# STM32C031K6U6 register map
File version: 1.0
Registers are 32-bit, access not given, reset 0x0 unless marked. A register's access mark holds for its fields unless they carry their own. Offsets are from the block's base; [hi:lo] are bit positions; {n}, {i} and the like mark numbered series; 'fields as' and 'values as' point back to an identical list.

## SYSCFG
Base 0x40010000
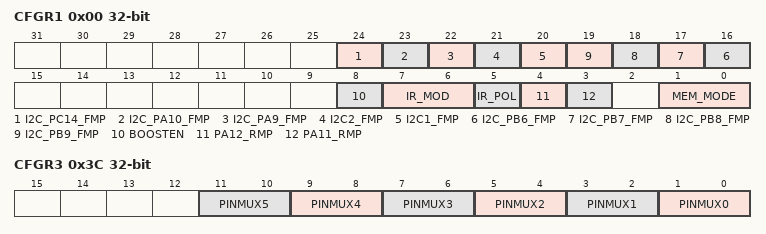
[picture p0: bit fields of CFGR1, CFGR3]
0x00 CFGR1
  [24] I2C_PC14_FMP, [23] I2C_PA10_FMP, [22] I2C_PA9_FMP, [21] I2C2_FMP, [20] I2C1_FMP, [n+10] I2C_PB{n}_FMP (n=6..9), [8] BOOSTEN, [7:6] IR_MOD, [5] IR_POL, [4] PA12_RMP, [3] PA11_RMP, [1:0] MEM_MODE
0x18 CFGR2
  [0] CLL
0x3C CFGR3
  [2n+1:2n] PINMUX{n} (n=0..5)
0x80 IT_LINE_SR.0
0x84 IT_LINE_SR.1
0x88 IT_LINE_SR.2
0x8C IT_LINE_SR.3
0x90 IT_LINE_SR.4
0x94 IT_LINE_SR.5
0x98 IT_LINE_SR.6
0x9C IT_LINE_SR.7
0xA0 IT_LINE_SR.8
0xA4 IT_LINE_SR.9
0xA8 IT_LINE_SR.10
0xAC IT_LINE_SR.11
0xB0 IT_LINE_SR.12
0xB4 IT_LINE_SR.13
0xB8 IT_LINE_SR.14
0xBC IT_LINE_SR.15
0xC0 IT_LINE_SR.16
0xC4 IT_LINE_SR.17
0xC8 IT_LINE_SR.18
0xCC IT_LINE_SR.19
0xD0 IT_LINE_SR.20
0xD4 IT_LINE_SR.21
0xD8 IT_LINE_SR.22
0xDC IT_LINE_SR.23
0xE0 IT_LINE_SR.24
0xE4 IT_LINE_SR.25
0xE8 IT_LINE_SR.26
0xEC IT_LINE_SR.27
0xF0 IT_LINE_SR.28
0xF4 IT_LINE_SR.29
0xF8 IT_LINE_SR.30
0xFC IT_LINE_SR.31

## ADC1
Base 0x40012400
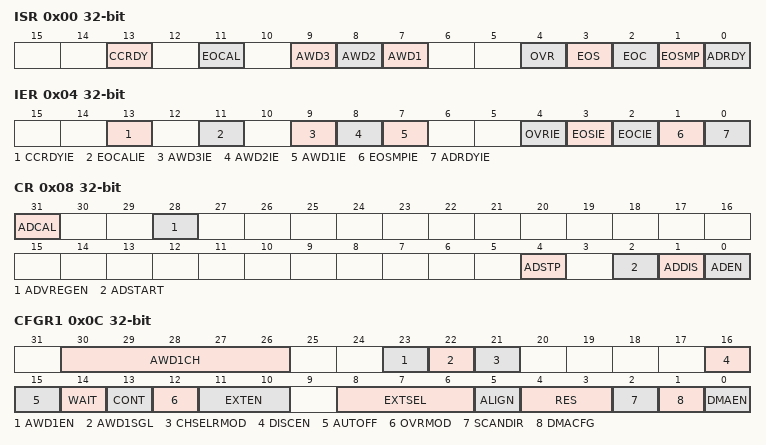
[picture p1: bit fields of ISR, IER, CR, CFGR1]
0x00 ISR
  [13] CCRDY, [11] EOCAL, [9] AWD3, [8] AWD2, [7] AWD1, [4] OVR, [3] EOS, [2] EOC, [1] EOSMP, [0] ADRDY
0x04 IER
  [13] CCRDYIE, [11] EOCALIE, [9] AWD3IE, [8] AWD2IE, [7] AWD1IE, [4] OVRIE, [3] EOSIE, [2] EOCIE, [1] EOSMPIE, [0] ADRDYIE
0x08 CR
  [31] ADCAL, [28] ADVREGEN, [4] ADSTP, [2] ADSTART, [1] ADDIS, [0] ADEN
0x0C CFGR1
  [30:26] AWD1CH, [23] AWD1EN, [22] AWD1SGL, [21] CHSELRMOD, [16] DISCEN, [15] AUTOFF, [14] WAIT, [13] CONT, [12] OVRMOD, [11:10] EXTEN, [8:6] EXTSEL, [5] ALIGN, [4:3] RES, [2] SCANDIR, [1] DMACFG, [0] DMAEN
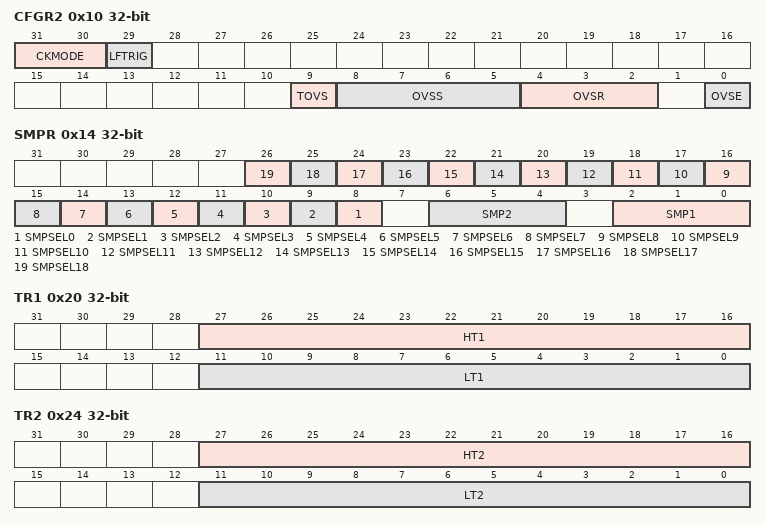
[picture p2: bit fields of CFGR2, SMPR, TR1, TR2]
0x10 CFGR2
  [31:30] CKMODE, [29] LFTRIG, [9] TOVS, [8:5] OVSS, [4:2] OVSR, [0] OVSE
0x14 SMPR
  [n+8] SMPSEL{n} (n=0..18), [6:4] SMP2, [2:0] SMP1
0x20 TR1
  [27:16] HT1, [11:0] LT1
0x24 TR2
  [27:16] HT2, [11:0] LT2
0x28 CHSELR
  [4n-1:4n-4] SQ{n} (n=2..8), [22] CHSEL22, [21] CHSEL21, [19] CHSEL19, [18] CHSEL18, [17] CHSEL17, [15] CHSEL15, [14] CHSEL14, [13] CHSEL13, [11] CHSEL11, [10] CHSEL10, [9] CHSEL9, [7] CHSEL7, [6] CHSEL6, [5] CHSEL5, [3] CHSEL3, [2] CHSEL2, [1] CHSEL1, [31:0] SQ_ALL
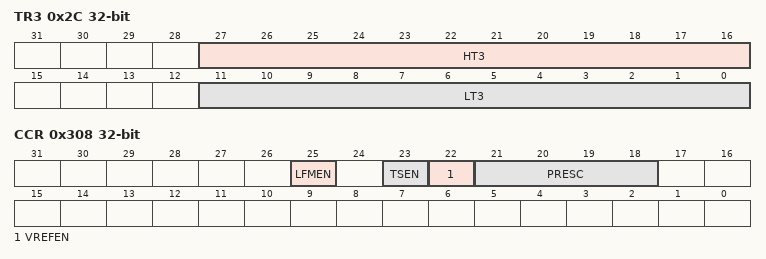
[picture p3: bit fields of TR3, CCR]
0x2C TR3
  [27:16] HT3, [11:0] LT3
0x40 DR
  [15:0] DATA
0xA0 AWD2CR
  [18:0] AWD2CH
0xA4 AWD3CR
  [18:0] AWD3CH
0xB4 CALFACT
  [6:0] CALFACT
0x308 CCR
  [25] LFMEN, [23] TSEN, [22] VREFEN, [21:18] PRESC

## SPI1
Base 0x40013000
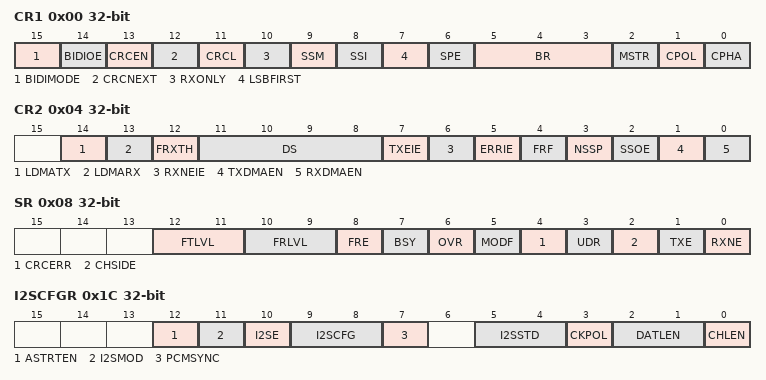
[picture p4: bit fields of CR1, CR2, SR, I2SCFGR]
0x00 CR1
  [15] BIDIMODE, [14] BIDIOE, [13] CRCEN, [12] CRCNEXT, [11] CRCL, [10] RXONLY, [9] SSM, [8] SSI, [7] LSBFIRST, [6] SPE, [5:3] BR, [2] MSTR, [1] CPOL, [0] CPHA
0x04 CR2
  [14] LDMATX, [13] LDMARX, [12] FRXTH, [11:8] DS, [7] TXEIE, [6] RXNEIE, [5] ERRIE, [4] FRF, [3] NSSP, [2] SSOE, [1] TXDMAEN, [0] RXDMAEN
0x08 SR
  [12:11] FTLVL, [10:9] FRLVL, [8] FRE, [7] BSY, [6] OVR, [5] MODF, [4] CRCERR, [3] UDR, [2] CHSIDE, [1] TXE, [0] RXNE
0x0C DR
  [15:0] DR
0x10 CRCPR
  [15:0] CRCPOLY
0x14 RXCRCR
  [15:0] RXCRC
0x18 TXCRCR
  [15:0] TXCRC
0x1C I2SCFGR
  [12] ASTRTEN, [11] I2SMOD, [10] I2SE, [9:8] I2SCFG, [7] PCMSYNC, [5:4] I2SSTD, [3] CKPOL, [2:1] DATLEN, [0] CHLEN
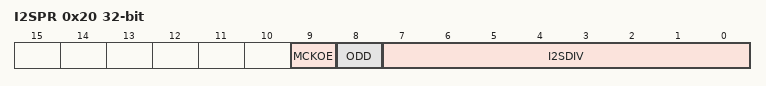
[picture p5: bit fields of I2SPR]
0x20 I2SPR
  [9] MCKOE, [8] ODD, [7:0] I2SDIV

## DBG
Base 0x40015800
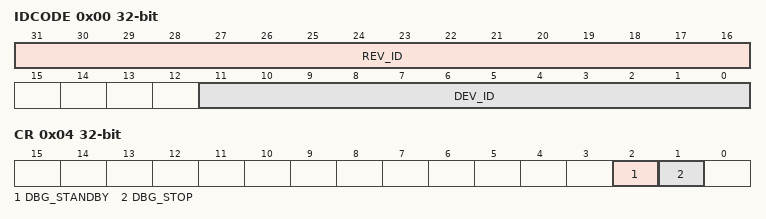
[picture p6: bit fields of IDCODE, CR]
0x00 IDCODE
  [31:16] REV_ID, [11:0] DEV_ID
0x04 CR
  [2] DBG_STANDBY, [1] DBG_STOP
0x08 APBFZ1
0x0C APBFZ2

## DMA1
Base 0x40020000
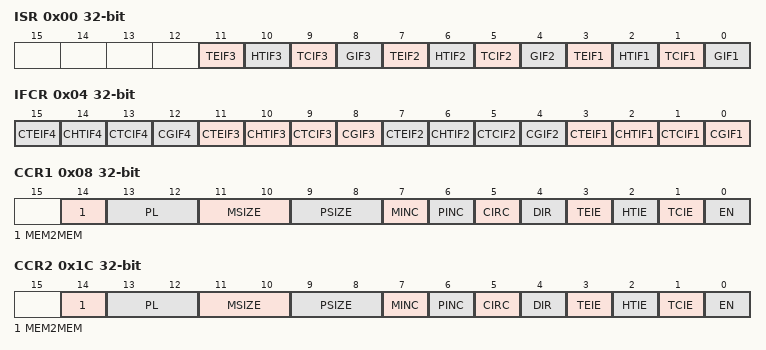
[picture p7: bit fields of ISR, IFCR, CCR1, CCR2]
0x00 ISR
  [11] TEIF3, [10] HTIF3, [9] TCIF3, [8] GIF3, [7] TEIF2, [6] HTIF2, [5] TCIF2, [4] GIF2, [3] TEIF1, [2] HTIF1, [1] TCIF1, [0] GIF1
0x04 IFCR
  [4n-1] CTEIF{n} (n=1..4), [4n-2] CHTIF{n} (n=1..4), [4n-3] CTCIF{n} (n=1..4), [4n-4] CGIF{n} (n=1..4)
0x08 CCR1
  [14] MEM2MEM, [13:12] PL, [11:10] MSIZE, [9:8] PSIZE, [7] MINC, [6] PINC, [5] CIRC, [4] DIR, [3] TEIE, [2] HTIE, [1] TCIE, [0] EN
0x0C CNDTR1
  [15:0] NDT
0x10 CPAR1
  [31:0] PA
{0x0+0x14*i} CMAR{i} (i=1..3)
  [31:0] MA
0x1C CCR2
  fields as CCR1
0x20 CNDTR2
  [15:0] NDT
0x24 CPAR2
  [31:0] PA
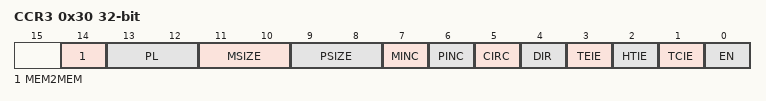
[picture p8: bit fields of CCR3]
0x30 CCR3
  fields as CCR1
0x34 CNDTR3
  [15:0] NDT
0x38 CPAR3
  [31:0] PA
